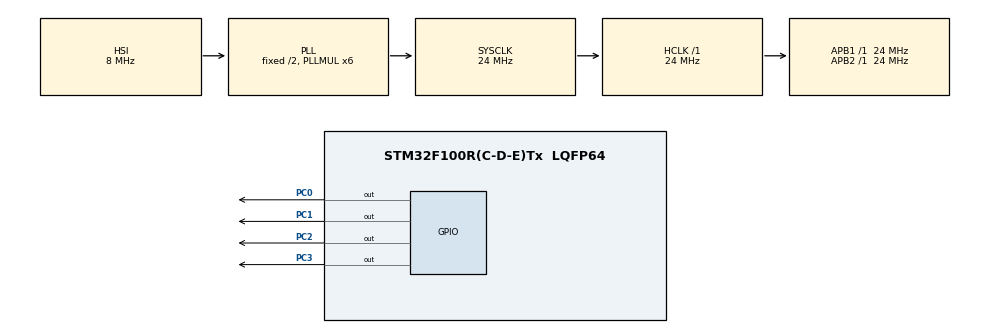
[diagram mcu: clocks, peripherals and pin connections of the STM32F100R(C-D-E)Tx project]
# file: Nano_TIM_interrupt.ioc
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Mcu.Family=STM32F1
Mcu.Name=STM32F100R(C-D-E)Tx
Mcu.Package=LQFP64
NVIC.PriorityGroup=NVIC_PRIORITYGROUP_4
NVIC.TIM3_IRQn=true\:0\:0\:false\:false\:true\:true\:true
NVIC.TIM6_DAC_IRQn=true\:0\:0\:false\:false\:true\:true\:true
PA13.Mode=Serial_Wire
PA13.Signal=SYS_JTMS-SWDIO
PA14.Mode=Serial_Wire
PA14.Signal=SYS_JTCK-SWCLK
PC0.Signal=GPIO_Output
PC1.Signal=GPIO_Output
PC14-OSC32_IN.Mode=LSE-External-Oscillator
PC14-OSC32_IN.Signal=RCC_OSC32_IN
PC15-OSC32_OUT.Mode=LSE-External-Oscillator
PC15-OSC32_OUT.Signal=RCC_OSC32_OUT
PC2.Signal=GPIO_Output
PC3.Signal=GPIO_Output
PD0-OSC_IN.Mode=HSE-External-Oscillator
PD0-OSC_IN.Signal=RCC_OSC_IN
PD1-OSC_OUT.Mode=HSE-External-Oscillator
PD1-OSC_OUT.Signal=RCC_OSC_OUT
ProjectManager.HeapSize=0x200
ProjectManager.StackSize=0x400
ProjectManager.TargetToolchain=MDK-ARM V5.27
RCC.AHBFreq_Value=24000000
RCC.APB1Freq_Value=24000000
RCC.APB1TimFreq_Value=24000000
RCC.APB2Freq_Value=24000000
RCC.APB2TimFreq_Value=24000000
RCC.HCLKFreq_Value=24000000
RCC.PLLMUL=RCC_PLL_MUL6
RCC.SYSCLKFreq_VALUE=24000000
RCC.SYSCLKSource=RCC_SYSCLKSOURCE_PLLCLK
TIM3.Period=1999
TIM3.Prescaler=24000
TIM6.Period=999
TIM6.Prescaler=24000
VP_TIM3_VS_ClockSourceINT.Mode=Internal
VP_TIM6_VS_ClockSourceINT.Mode=Enable_Timer
board=custom

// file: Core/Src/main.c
/* USER CODE BEGIN Header */
/**
  ******************************************************************************
  * @file           : main.c
  * @brief          : Main program body
  ******************************************************************************
  * @attention
  *
  * <h2><center>&copy; Copyright (c) 2021 STMicroelectronics.
  * All rights reserved.</center></h2>
  *
  * This software component is licensed by ST under BSD 3-Clause license,
  * the "License"; You may not use this file except in compliance with the
  * License. You may obtain a copy of the License at:
  *                        opensource.org/licenses/BSD-3-Clause
  *
  ******************************************************************************
  */
/* USER CODE END Header */
#include "main.h"

TIM_HandleTypeDef htim3;
TIM_HandleTypeDef htim6;

void SystemClock_Config(void);
static void MX_GPIO_Init(void);
static void MX_TIM3_Init(void);
static void MX_TIM6_Init(void);

/* USER CODE BEGIN 0 */
		void HAL_TIM_PeriodElapsedCallback(TIM_HandleTypeDef *htim)
		{
			if(htim->Instance== TIM3)
			{
				HAL_GPIO_TogglePin(GPIOC, GPIO_PIN_0);
			}
			if(htim->Instance== TIM6)
			{
				HAL_GPIO_TogglePin(GPIOC, GPIO_PIN_3);
			}
		}
/* USER CODE END 0 */

int main(void)
{

  /* MCU Configuration--------------------------------------------------------*/

  /* Reset of all peripherals, Initializes the Flash interface and the Systick. */
  HAL_Init();

  /* Configure the system clock */
  SystemClock_Config();

  /* Initialize all configured peripherals */
  MX_GPIO_Init();
  MX_TIM3_Init();
  MX_TIM6_Init();
  /* USER CODE BEGIN 2 */
	HAL_TIM_Base_Start_IT(&htim3);
	HAL_TIM_Base_Start_IT(&htim6);
  /* USER CODE END 2 */

  /* Infinite loop */
  while (1)
  {

    /* USER CODE BEGIN 3 */
		HAL_GPIO_TogglePin(GPIOC, GPIO_PIN_2);
		HAL_Delay(500);
		HAL_GPIO_TogglePin(GPIOC, GPIO_PIN_1);
		HAL_Delay(1000);
  }
  /* USER CODE END 3 */
}

void SystemClock_Config(void)
{
  RCC_OscInitTypeDef RCC_OscInitStruct = {0};
  RCC_ClkInitTypeDef RCC_ClkInitStruct = {0};

  /** Initializes the RCC Oscillators according to the specified parameters
  * in the RCC_OscInitTypeDef structure.
  */
  RCC_OscInitStruct.OscillatorType = RCC_OSCILLATORTYPE_HSI;
  RCC_OscInitStruct.HSIState = RCC_HSI_ON;
  RCC_OscInitStruct.HSICalibrationValue = RCC_HSICALIBRATION_DEFAULT;
  RCC_OscInitStruct.PLL.PLLState = RCC_PLL_ON;
  RCC_OscInitStruct.PLL.PLLSource = RCC_PLLSOURCE_HSI_DIV2;
  RCC_OscInitStruct.PLL.PLLMUL = RCC_PLL_MUL6;
  if (HAL_RCC_OscConfig(&RCC_OscInitStruct) != HAL_OK)
  {
    Error_Handler();
  }
  /** Initializes the CPU, AHB and APB buses clocks
  */
  RCC_ClkInitStruct.ClockType = RCC_CLOCKTYPE_HCLK|RCC_CLOCKTYPE_SYSCLK
                              |RCC_CLOCKTYPE_PCLK1|RCC_CLOCKTYPE_PCLK2;
  RCC_ClkInitStruct.SYSCLKSource = RCC_SYSCLKSOURCE_PLLCLK;
  RCC_ClkInitStruct.AHBCLKDivider = RCC_SYSCLK_DIV1;
  RCC_ClkInitStruct.APB1CLKDivider = RCC_HCLK_DIV1;
  RCC_ClkInitStruct.APB2CLKDivider = RCC_HCLK_DIV1;

  if (HAL_RCC_ClockConfig(&RCC_ClkInitStruct, FLASH_LATENCY_0) != HAL_OK)
  {
    Error_Handler();
  }
}

static void MX_TIM3_Init(void)
{

  TIM_ClockConfigTypeDef sClockSourceConfig = {0};
  TIM_MasterConfigTypeDef sMasterConfig = {0};

  htim3.Instance = TIM3;
  htim3.Init.Prescaler = 24000;
  htim3.Init.CounterMode = TIM_COUNTERMODE_UP;
  htim3.Init.Period = 1999;
  htim3.Init.ClockDivision = TIM_CLOCKDIVISION_DIV1;
  htim3.Init.AutoReloadPreload = TIM_AUTORELOAD_PRELOAD_DISABLE;
  if (HAL_TIM_Base_Init(&htim3) != HAL_OK)
  {
    Error_Handler();
  }
  sClockSourceConfig.ClockSource = TIM_CLOCKSOURCE_INTERNAL;
  if (HAL_TIM_ConfigClockSource(&htim3, &sClockSourceConfig) != HAL_OK)
  {
    Error_Handler();
  }
  sMasterConfig.MasterOutputTrigger = TIM_TRGO_RESET;
  sMasterConfig.MasterSlaveMode = TIM_MASTERSLAVEMODE_DISABLE;
  if (HAL_TIMEx_MasterConfigSynchronization(&htim3, &sMasterConfig) != HAL_OK)
  {
    Error_Handler();
  }

}

static void MX_TIM6_Init(void)
{

  TIM_MasterConfigTypeDef sMasterConfig = {0};

  htim6.Instance = TIM6;
  htim6.Init.Prescaler = 24000;
  htim6.Init.CounterMode = TIM_COUNTERMODE_UP;
  htim6.Init.Period = 999;
  htim6.Init.AutoReloadPreload = TIM_AUTORELOAD_PRELOAD_DISABLE;
  if (HAL_TIM_Base_Init(&htim6) != HAL_OK)
  {
    Error_Handler();
  }
  sMasterConfig.MasterOutputTrigger = TIM_TRGO_RESET;
  sMasterConfig.MasterSlaveMode = TIM_MASTERSLAVEMODE_DISABLE;
  if (HAL_TIMEx_MasterConfigSynchronization(&htim6, &sMasterConfig) != HAL_OK)
  {
    Error_Handler();
  }

}

static void MX_GPIO_Init(void)
{
  GPIO_InitTypeDef GPIO_InitStruct = {0};

  /* GPIO Ports Clock Enable */
  __HAL_RCC_GPIOC_CLK_ENABLE();
  __HAL_RCC_GPIOD_CLK_ENABLE();
  __HAL_RCC_GPIOA_CLK_ENABLE();

  /*Configure GPIO pin Output Level */
  HAL_GPIO_WritePin(GPIOC, GPIO_PIN_0|GPIO_PIN_1|GPIO_PIN_2|GPIO_PIN_3, GPIO_PIN_RESET);

  /*Configure GPIO pins : PC0 PC1 PC2 PC3 */
  GPIO_InitStruct.Pin = GPIO_PIN_0|GPIO_PIN_1|GPIO_PIN_2|GPIO_PIN_3;
  GPIO_InitStruct.Mode = GPIO_MODE_OUTPUT_PP;
  GPIO_InitStruct.Pull = GPIO_NOPULL;
  GPIO_InitStruct.Speed = GPIO_SPEED_FREQ_LOW;
  HAL_GPIO_Init(GPIOC, &GPIO_InitStruct);

}

void Error_Handler(void)
{
}

/************************ (C) COPYRIGHT STMicroelectronics *****END OF FILE****/
